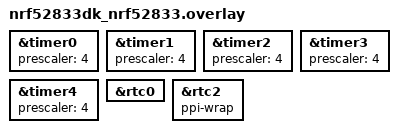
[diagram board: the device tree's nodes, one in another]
&timer0 {
	status = "okay";
	prescaler = <4>;
};

&timer1 {
	status = "okay";
	prescaler = <4>;
};

&timer2 {
	status = "okay";
	prescaler = <4>;
};

&timer3 {
	status = "okay";
	prescaler = <4>;
};

&timer4 {
	status = "okay";
	prescaler = <4>;
};

&rtc0 {
	status = "okay";
};

&rtc2 {
	status = "okay";
	ppi-wrap;
};
